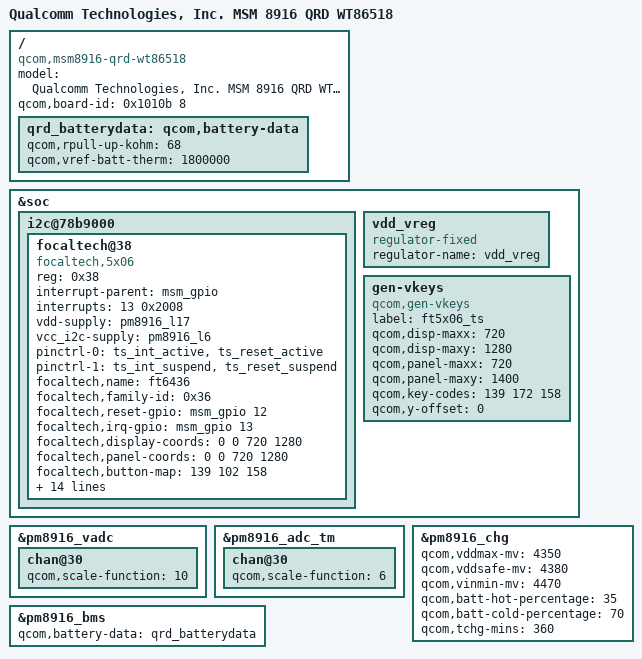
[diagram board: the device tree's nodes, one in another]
/* Copyright (c) 2014, The Linux Foundation. All rights reserved.
 *
 * This program is free software; you can redistribute it and/or modify
 * it under the terms of the GNU General Public License version 2 and
 * only version 2 as published by the Free Software Foundation.
 *
 * This program is distributed in the hope that it will be useful,
 * but WITHOUT ANY WARRANTY; without even the implied warranty of
 * MERCHANTABILITY or FITNESS FOR A PARTICULAR PURPOSE.  See the
 * GNU General Public License for more details.
 */

/dts-v1/;

#include "msm8916-qrd.dtsi"
#include "msm8916-memory.dtsi"
#include "wt86518/msm8916-wt86518.dtsi"

/ {
	model = "Qualcomm Technologies, Inc. MSM 8916 QRD WT86518";
	compatible = "qcom,msm8916-qrd-wt86518", "qcom,msm8916-qrd", "qcom,msm8916", "qcom,qrd";
	qcom,board-id = <0x1010b 8>;          
};

&soc {
	i2c@78b9000 { /* BLSP1 QUP5 */
		focaltech@38 {
			compatible = "focaltech,5x06";
			reg = <0x38>;
			interrupt-parent = <&msm_gpio>;
			interrupts = <13 0x2008>;
			vdd-supply = <&pm8916_l17>;
			vcc_i2c-supply = <&pm8916_l6>;
			/* pins used by touchscreen */
			pinctrl-names = "pmx_ts_active","pmx_ts_suspend";
			pinctrl-0 = <&ts_int_active &ts_reset_active>;
			pinctrl-1 = <&ts_int_suspend &ts_reset_suspend>;
			focaltech,name = "ft6436";
			focaltech,family-id = <0x36>;
			focaltech,reset-gpio = <&msm_gpio 12 0x0>;
			focaltech,irq-gpio = <&msm_gpio 13 0x2008>;
			focaltech,display-coords = <0 0 720 1280>;
			focaltech,panel-coords = <0 0 720 1280>;
			focaltech,button-map= <139 102 158>;
			focaltech,no-force-update;
			focaltech,i2c-pull-up;
			focaltech,group-id = <1>;
			focaltech,hard-reset-delay-ms = <20>;
			focaltech,soft-reset-delay-ms = <200>;
			focaltech,num-max-touches = <5>;
			focaltech,fw-delay-aa-ms = <30>;
			focaltech,fw-delay-55-ms = <30>;
			focaltech,fw-upgrade-id1 = <0x79>;
			focaltech,fw-upgrade-id2 = <0x18>;
			focaltech,fw-delay-readid-ms = <10>;
			focaltech,fw-delay-era-flsh-ms = <2000>;
			focaltech,fw-auto-cal;
			focaltech,ignore-id-check;
		};
	};

	vdd_vreg: vdd_vreg {
		compatible = "regulator-fixed";
		status = "ok";
		regulator-name = "vdd_vreg";
	};

	gen-vkeys {
		compatible = "qcom,gen-vkeys";
		label = "ft5x06_ts";
		qcom,disp-maxx = <720>;
		qcom,disp-maxy = <1280>;
		qcom,panel-maxx = <720>;
		qcom,panel-maxy = <1400>;
		qcom,key-codes = <139 172 158>;
		qcom,y-offset = <0>;
	};
};

&pm8916_vadc {
	chan@30 {
		qcom,scale-function = <10>;
	};
};

&pm8916_adc_tm {
	chan@30 {
		qcom,scale-function = <6>;
	};
};

&pm8916_chg {
	qcom,vddmax-mv = <4350>;
	qcom,vddsafe-mv = <4380>;
	qcom,vinmin-mv = <4470>;
	qcom,batt-hot-percentage = <35>;
	qcom,batt-cold-percentage = <70>;
	qcom,tchg-mins = <360>;
	status = "okay";
};

/ {
	qrd_batterydata: qcom,battery-data {
		qcom,rpull-up-kohm = <68>;
		qcom,vref-batt-therm = <1800000>;

		#include "batterydata-qrd-skuh-4v35-2000mah.dtsi"
	};
};

&pm8916_bms {
	status = "ok";
	qcom,battery-data = <&qrd_batterydata>;
};                                                                                     
